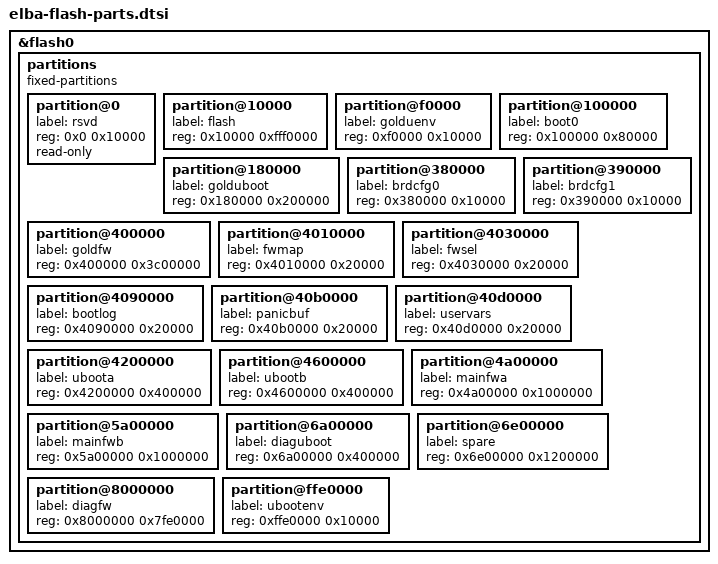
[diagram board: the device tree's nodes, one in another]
// SPDX-License-Identifier: (GPL-2.0-only OR BSD-2-Clause)
/*
 * Copyright 2020-2023 Advanced Micro Devices, Inc.
 */

&flash0 {
	partitions {
		compatible = "fixed-partitions";
		#address-cells = <1>;
		#size-cells = <1>;
		partition@0 {
			label = "rsvd";
			reg = <0x0 0x10000>;
			read-only;
		};

		partition@10000 {
			label = "flash";
			reg = <0x10000 0xfff0000>;
		};

		partition@f0000 {
			label = "golduenv";
			reg = <0xf0000 0x10000>;
		};

		partition@100000 {
			label = "boot0";
			reg = <0x100000 0x80000>;
		};

		partition@180000 {
			label = "golduboot";
			reg = <0x180000 0x200000>;
		};

		partition@380000 {
			label = "brdcfg0";
			reg = <0x380000 0x10000>;
		};

		partition@390000 {
			label = "brdcfg1";
			reg = <0x390000 0x10000>;
		};

		partition@400000 {
			label = "goldfw";
			reg = <0x400000 0x3c00000>;
		};

		partition@4010000 {
			label = "fwmap";
			reg = <0x4010000 0x20000>;
		};

		partition@4030000 {
			label = "fwsel";
			reg = <0x4030000 0x20000>;
		};

		partition@4090000 {
			label = "bootlog";
			reg = <0x4090000 0x20000>;
		};

		partition@40b0000 {
			label = "panicbuf";
			reg = <0x40b0000 0x20000>;
		};

		partition@40d0000 {
			label = "uservars";
			reg = <0x40d0000 0x20000>;
		};

		partition@4200000 {
			label = "uboota";
			reg = <0x4200000 0x400000>;
		};

		partition@4600000 {
			label = "ubootb";
			reg = <0x4600000 0x400000>;
		};

		partition@4a00000 {
			label = "mainfwa";
			reg = <0x4a00000 0x1000000>;
		};

		partition@5a00000 {
			label = "mainfwb";
			reg = <0x5a00000 0x1000000>;
		};

		partition@6a00000 {
			label = "diaguboot";
			reg = <0x6a00000 0x400000>;
		};

		partition@6e00000 {
			label = "spare";
			reg = <0x6e00000 0x1200000>;
		};

		partition@8000000 {
			label = "diagfw";
			reg = <0x8000000 0x7fe0000>;
		};

		partition@ffe0000 {
			label = "ubootenv";
			reg = <0xffe0000 0x10000>;
		};
	};
};
